AUTOSAR XML (schema 00046)
standard types defined: dtRef_const_VOID, dtRef_VOID, boolean, float32, float64, sint16, sint16_least, sint32, sint32_least, sint64, sint8, sint8_least, uint16, uint16_least, uint32, uint32_least, uint64, uint8, uint8_least, boolean_CompuMethod, boolean_DataConstr, float32_DataConstr, float64_DataConstr, sint16_DataConstr, sint16_least_DataConstr, sint32_DataConstr, sint32_least_DataConstr, sint64_DataConstr, sint8_DataConstr, sint8_least_DataConstr, uint16_DataConstr, uint16_least_DataConstr, uint32_DataConstr, uint32_least_DataConstr, uint64_DataConstr, uint8_DataConstr, uint8_least_DataConstr
package /ComponentTypes
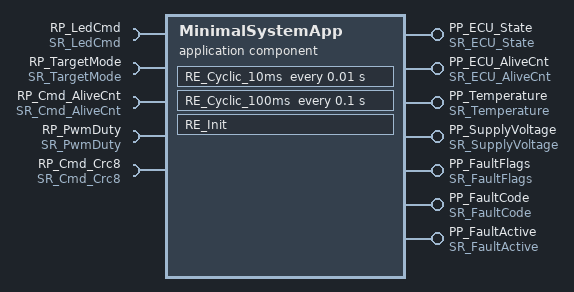
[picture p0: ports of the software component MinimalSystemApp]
  application sw component type MinimalSystemApp
    7 x provide port:
      PP_ECU_State: nonqueued-sender-com-spec{data-element=ECU_State, init-value=0}, provided-interface=SR_ECU_State
      PP_ECU_AliveCnt: nonqueued-sender-com-spec{data-element=ECU_AliveCnt, init-value=0}, provided-interface=SR_ECU_AliveCnt
      PP_Temperature: nonqueued-sender-com-spec{data-element=Temperature, init-value=0}, provided-interface=SR_Temperature
      PP_SupplyVoltage: nonqueued-sender-com-spec{data-element=SupplyVoltage, init-value=0}, provided-interface=SR_SupplyVoltage
      PP_FaultFlags: nonqueued-sender-com-spec{data-element=FaultFlags, init-value=0}, provided-interface=SR_FaultFlags
      PP_FaultCode: nonqueued-sender-com-spec{data-element=FaultCode, init-value=0}, provided-interface=SR_FaultCode
      PP_FaultActive: nonqueued-sender-com-spec{data-element=FaultActive, init-value=0}, provided-interface=SR_FaultActive
    5 x require port:
      RP_LedCmd: nonqueued-receiver-com-spec{data-element=LedCmd, init-value=0}, required-interface=SR_LedCmd
      RP_TargetMode: nonqueued-receiver-com-spec{data-element=TargetMode, init-value=0}, required-interface=SR_TargetMode
      RP_Cmd_AliveCnt: nonqueued-receiver-com-spec{data-element=Cmd_AliveCnt, init-value=0}, required-interface=SR_Cmd_AliveCnt
      RP_PwmDuty: nonqueued-receiver-com-spec{data-element=PwmDuty, init-value=0}, required-interface=SR_PwmDuty
      RP_Cmd_Crc8: nonqueued-receiver-com-spec{data-element=Cmd_Crc8, init-value=0}, required-interface=SR_Cmd_Crc8
    behavior MinimalSystemApp_IB
      init event InitEvent: start-on-event=RE_Init
      timing event TimingEvent_10ms: start-on-event=RE_Cyclic_10ms, offset=0, period=0.01
      timing event TimingEvent_100ms: start-on-event=RE_Cyclic_100ms, offset=0, period=0.1
      runnable RE_Init
      runnable RE_Cyclic_10ms
        data-read-access:
          5 x access:
            REC_RP_LedCmd_LedCmd: accessed-variable=RP_LedCmd.LedCmd
            REC_RP_TargetMode_TargetMode: accessed-variable=RP_TargetMode.TargetMode
            REC_RP_Cmd_AliveCnt_Cmd_AliveCnt: accessed-variable=RP_Cmd_AliveCnt.Cmd_AliveCnt
            REC_RP_PwmDuty_PwmDuty: accessed-variable=RP_PwmDuty.PwmDuty
            REC_RP_Cmd_Crc8_Cmd_Crc8: accessed-variable=RP_Cmd_Crc8.Cmd_Crc8
        data-write-access:
          access SND_PP_FaultFlags_FaultFlags: accessed-variable=PP_FaultFlags.FaultFlags
          access SND_PP_FaultCode_FaultCode: accessed-variable=PP_FaultCode.FaultCode
          access SND_PP_FaultActive_FaultActive: accessed-variable=PP_FaultActive.FaultActive
      runnable RE_Cyclic_100ms
        data-write-access:
          4 x access:
            SND_PP_ECU_State_ECU_State: accessed-variable=PP_ECU_State.ECU_State
            SND_PP_ECU_AliveCnt_ECU_AliveCnt: accessed-variable=PP_ECU_AliveCnt.ECU_AliveCnt
            SND_PP_Temperature_Temperature: accessed-variable=PP_Temperature.Temperature
            SND_PP_SupplyVoltage_SupplyVoltage: accessed-variable=PP_SupplyVoltage.SupplyVoltage
  swc implementation MinimalSystemApp_Impl: behavior=MinimalSystemApp_IB
package /PortInterfaces
  12 x sender receiver interface:
    SR_ECU_State
      data ECU_State: type=uint4
    SR_ECU_AliveCnt
      data ECU_AliveCnt: type=uint4
    SR_Temperature
      data Temperature: type=uint8
    SR_SupplyVoltage
      data SupplyVoltage: type=uint16
    SR_FaultFlags
      data FaultFlags: type=uint8
    SR_LedCmd
      data LedCmd: type=uint1
    SR_TargetMode
      data TargetMode: type=uint3
    SR_Cmd_AliveCnt
      data Cmd_AliveCnt: type=uint4
    SR_PwmDuty
      data PwmDuty: type=uint8
    SR_Cmd_Crc8
      data Cmd_Crc8: type=uint8
    SR_FaultCode
      data FaultCode: type=uint8
    SR_FaultActive
      data FaultActive: type=uint1
package /DataTypes/BaseTypes
  base type uint1: base-type-size=1, native-declaration=uint8, category=FIXED_LENGTH
  base type uint3: base-type-size=3, native-declaration=uint8, category=FIXED_LENGTH
  base type uint4: base-type-size=4, native-declaration=uint8, category=FIXED_LENGTH
package /DataTypes/ImplementationDataTypes
  impl type uint1: category=VALUE, base-type=uint1
  impl type uint3: category=VALUE, base-type=uint3
  impl type uint4: category=VALUE, base-type=uint4
